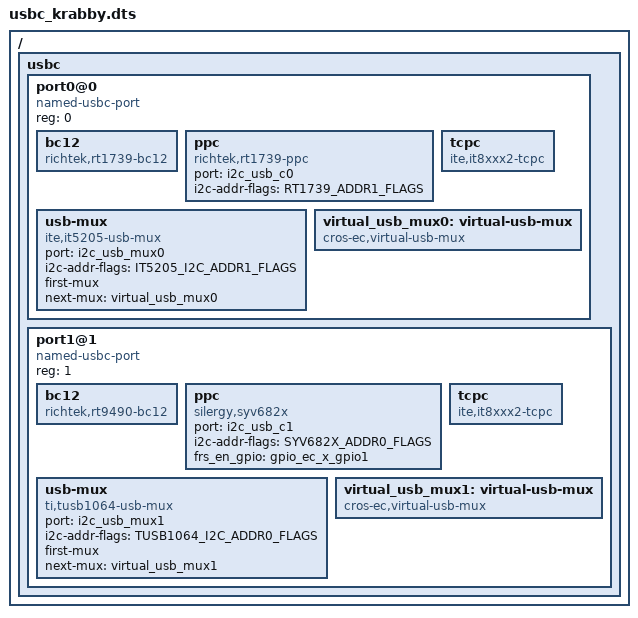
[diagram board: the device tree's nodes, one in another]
/* Copyright 2021 The Chromium OS Authors. All rights reserved.
 * Use of this source code is governed by a BSD-style license that can be
 * found in the LICENSE file.
 */

/ {
	usbc {
		#address-cells = <1>;
		#size-cells = <0>;

		port0@0 {
			compatible = "named-usbc-port";
			reg = <0>;
			bc12 {
				compatible = "richtek,rt1739-bc12";
				status = "okay";
			};
			ppc {
				compatible = "richtek,rt1739-ppc";
				status = "okay";
				port = <&i2c_usb_c0>;
				i2c-addr-flags = "RT1739_ADDR1_FLAGS";
			};
			tcpc {
				compatible = "ite,it8xxx2-tcpc";
			};
			usb-mux {
				compatible = "ite,it5205-usb-mux";
				port = <&i2c_usb_mux0>;
				i2c-addr-flags = "IT5205_I2C_ADDR1_FLAGS";
				first-mux;
				next-mux = <&virtual_usb_mux0>;
			};
			virtual_usb_mux0: virtual-usb-mux {
				compatible = "cros-ec,virtual-usb-mux";
			};
		};

		port1@1 {
			compatible = "named-usbc-port";
			reg = <1>;
			bc12 {
				compatible = "richtek,rt9490-bc12";
				status = "okay";
			};
			ppc {
				compatible = "silergy,syv682x";
				status = "okay";
				port = <&i2c_usb_c1>;
				i2c-addr-flags = "SYV682X_ADDR0_FLAGS";
				frs_en_gpio = <&gpio_ec_x_gpio1>;
			};
			tcpc {
				compatible = "ite,it8xxx2-tcpc";
			};
			usb-mux {
				compatible = "ti,tusb1064-usb-mux";
				port = <&i2c_usb_mux1>;
				i2c-addr-flags = "TUSB1064_I2C_ADDR0_FLAGS";
				first-mux;
				next-mux = <&virtual_usb_mux1>;
			};
			virtual_usb_mux1: virtual-usb-mux {
				compatible = "cros-ec,virtual-usb-mux";
			};
		};
	};
};
